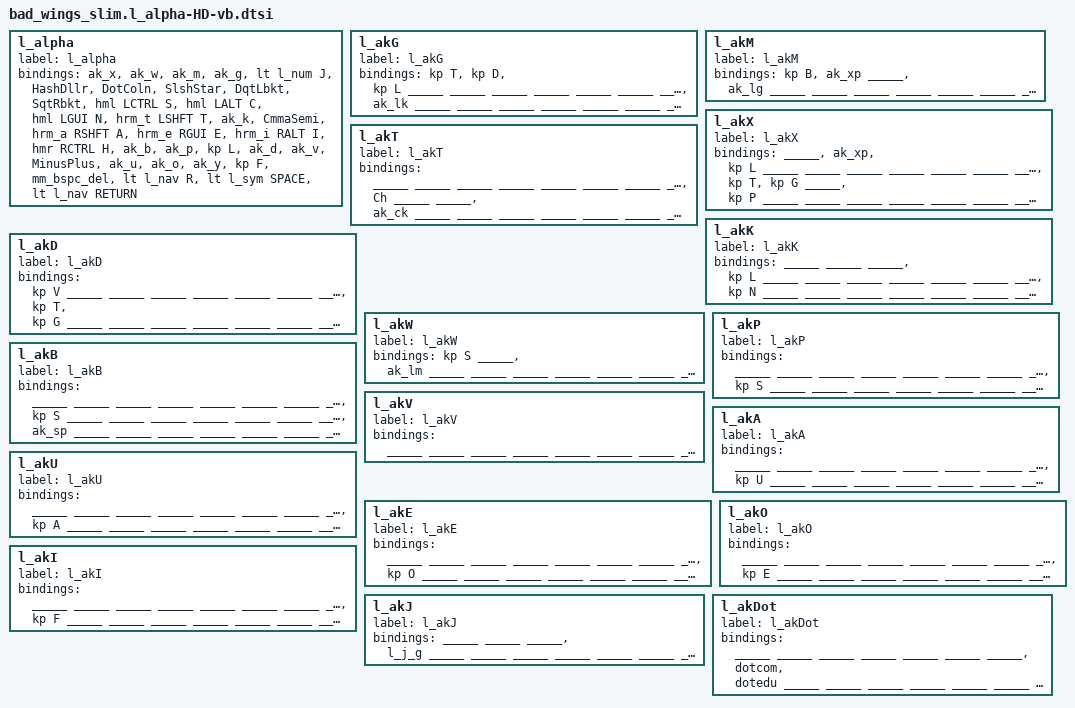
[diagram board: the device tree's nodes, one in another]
#define _____  &trans
/*    KEY POSITION Numbers for Zaphod
 ╭────────────────────╮ ╭────────────────────╮
 │  0   1   2   3   4 │ │  5   6   7   8   9 │
 │ 10  11  12  13  14 │ │ 15  16  17  18  19 |
 | 20  21  22  23  24 │ │ 25  26  27  28  29 |
 ╰───────────╮ 30  31 | | 32  33  ╭──────────╯
             ╰────────╯ ╰─────────╯
*/
/*    KEY POSITION Names
╭─────────────────────╮ ╭─────────────────────╮
│ LT4 LT3 LT2 LT1 LT0 │ │ RT0 RT1 RT2 RT3 RT4 │
│ LM4 LM3 LM2 LM1 LM0 │ │ RM0 RM1 RM2 RM3 RM4 │
│ LB4 LB3 LB2 LB1 LB0 │ │ RB0 RB1 RB2 RB3 RB4 │
╰───────────╮ LH2 LH1 | | RH1 RH2 ╭───────────╯
            ╰─────────╯ ╰─────────╯
*/
/*  Base (alpha) Layer  Hands Down Vibranium-vb
        Building for a 34 key board
╭─────────────────────╮ ╭──────────────────────╮
│  X   W   M   G   J  │ │  #$  .:  /*  "[  ']  │
│  S   C   N   T   K  | |  ,;   A   E   I   H  │
│  B   P   L   D   V  │ │  -+   U   O   Y   F  │
╰──────────╮  BSP  R  │ │  SPC RET  ╭──────────╯
           ╰──────────╯ ╰───────────╯
*/

                l_alpha {
                        label = "l_alpha";
                        bindings = <

//   &none &none &none &none &none   &none &none &none &none &none
//   &none &none &none &none &none   &none &none &none &none &none
//   &none &none &none &none &none   &none &none &none &none &none
//                     &none &none   &none &none

&ak_x   &ak_w   &ak_m     &ak_g     &lt l_num J           &HashDllr     &DotColn    &SlshStar   &DqtLbkt   &SqtRbkt
&hml LCTRL S &hml LALT C   &hml LGUI N  &hrm_t LSHFT T &ak_k    &CmmaSemi  &hrm_a RSHFT A &hrm_e RGUI E  &hrm_i RALT I  &hmr RCTRL H
&ak_b   &ak_p   &kp L     &ak_d     &ak_v                 &MinusPlus    &ak_u       &ak_o       &ak_y      &kp F


                &mm_bspc_del &lt l_nav R      &lt l_sym SPACE &lt l_nav RETURN
                        >;
                };

                l_akG {
                        label = "l_akG";
                        bindings = <

&kp T   &kp D   &kp L   _____     _____     _____     _____     _____     _____     _____
_____     _____     _____     _____     &ak_lk  _____     _____     _____     _____     _____
_____     _____     _____     _____     _____    _____     _____     _____     _____     _____
                        _____     _____     _____     _____
                        >;
                };
                l_akM {
                        label = "l_akM";
                        bindings = <

&kp B   &ak_xp  _____     &ak_lg  _____    _____     _____     _____     _____     _____
_____     _____     _____     _____     _____    _____     _____     _____     _____     _____
_____     _____     _____     _____     _____    _____     _____     _____     _____     _____
                        _____     _____    _____     _____
                        >;
                };
                l_akX {
                        label = "l_akX";
                        bindings = <

_____     &ak_xp  &kp L   _____     _____    _____     _____     _____     _____     _____
_____     _____     _____     _____     _____    _____     _____     _____     _____     _____
&kp T   &kp G   _____     &kp P   _____    _____     _____     _____     _____     _____
                        _____     _____    _____     _____
                        >;
                };
                l_akT {
                        label = "l_akT";
                        bindings = <

_____     _____     _____     _____     _____    _____     _____     _____     _____     _____
_____     &Ch     _____     _____    &ak_ck  _____     _____     _____     _____     _____
_____     _____     _____     _____     _____    _____     _____     _____     _____     _____
                        _____     _____    _____     _____
                        >;
                };
                l_akK {
                        label = "l_akK";
                        bindings = <

_____     _____     _____     &kp L   _____    _____     _____     _____     _____     _____
_____     _____     _____     &kp N   _____    _____     _____     _____     _____     _____
_____     _____     _____     _____     _____    _____     _____     _____     _____     _____
                        _____     _____    _____     _____
                        >;
                };
                l_akD {
                        label = "l_akD";
                        bindings = <

&kp V   _____     _____     _____     _____    _____     _____     _____     _____     _____
_____     _____     _____     _____     _____    _____     _____     _____     _____     _____
&kp T   &kp G   _____     _____     _____    _____     _____     _____     _____     _____
                        _____     _____    _____     _____
                        >;
                };
                l_akW {
                        label = "l_akW";
                        bindings = <

&kp S   _____     &ak_lm  _____     _____    _____     _____     _____     _____     _____
_____     _____     _____     _____     _____    _____     _____     _____     _____     _____
_____     _____     _____     _____     _____    _____     _____     _____     _____     _____
                        _____     _____    _____     _____
                        >;
                };
                l_akP {
                        label = "l_akP";
                        bindings = <

_____     _____     _____     _____     _____    _____     _____     _____     _____     _____
_____     _____     _____     _____     _____    _____     _____     _____     _____     _____
&kp S   _____     _____     _____     _____    _____     _____     _____     _____     _____
                        _____     _____    _____     _____
                        >;
                };
                l_akB {
                        label = "l_akB";
                        bindings = <

_____     _____     _____     _____     _____    _____     _____     _____     _____     _____
_____     &kp S   _____     _____     _____    _____     _____     _____     _____     _____
_____     &ak_sp  _____     _____     _____    _____     _____     _____     _____     _____
                        _____     _____    _____     _____
                        >;
                };
                l_akV {
                        label = "l_akV";
                        bindings = <

_____     _____     _____     _____     _____    _____     _____     _____     _____     _____
_____     _____     _____     _____     _____    _____     _____     _____     _____     _____
_____     _____     _____     _____     _____    _____     _____     _____     _____     _____
                        _____     _____    _____     _____
                        >;
                };



                l_akA {
                        label = "l_akA";
                        bindings = <

_____     _____     _____     _____     _____    _____     _____     _____     _____     _____
_____     _____     _____     _____     _____    _____     _____     _____     _____     &kp U
_____     _____     _____     _____     _____    _____     _____     _____     _____     _____
                        _____     _____    _____     _____
                        >;
                };

                l_akU {
                        label = "l_akU";
                        bindings = <

_____     _____     _____     _____     _____    _____     _____     _____     _____     _____
_____     _____     _____     _____     _____    _____     _____     _____     _____     &kp A
_____     _____     _____     _____     _____    _____     _____     _____     _____     _____
                        _____     _____    _____     _____
                        >;
                };

                l_akE {
                        label = "l_akE";
                        bindings = <

_____     _____     _____     _____     _____    _____     _____     _____     _____     _____
_____     _____     _____     _____     _____    _____     _____     _____     _____     &kp O
_____     _____     _____     _____     _____    _____     _____     _____     _____     _____
                        _____     _____    _____     _____
                        >;
                };
                l_akO {
                        label = "l_akO";
                        bindings = <

_____     _____     _____     _____     _____    _____     _____     _____     _____     _____
_____     _____     _____     _____     _____    _____     _____     _____     _____     &kp E
_____     _____     _____     _____     _____    _____     _____     _____     _____     _____
                        _____     _____    _____     _____
                        >;
                };
                l_akI {
                        label = "l_akI";
                        bindings = <

_____     _____     _____     _____     _____    _____     _____     _____     _____     _____
_____     _____     _____     _____     _____    _____     _____     _____     _____     &kp F
_____     _____     _____     _____     _____    _____     _____     _____     _____     _____
                        _____     _____    _____     _____
                        >;
                };
                l_akJ {
                        label = "l_akJ";
                        bindings = <
_____   _____   _____   &l_j_g  _____       _____   _____   _____   _____   _____
_____   _____   _____   _____   _____       _____   _____   _____   _____   _____
_____   _____   _____   _____   _____       _____   _____   _____   _____   _____
                _____   _____   _____       _____   _____   _____
                            >;
                };

                l_akDot {
                        label = "l_akDot";
                        bindings = <

_____     _____     _____     _____     _____    _____     _____     &dotcom &dotedu _____
_____     _____     _____     _____     _____    _____     _____     _____     _____     _____
_____     _____     _____     _____     _____    _____     _____     _____     _____     _____
                        _____     _____    _____     _____
                        >;
                };
